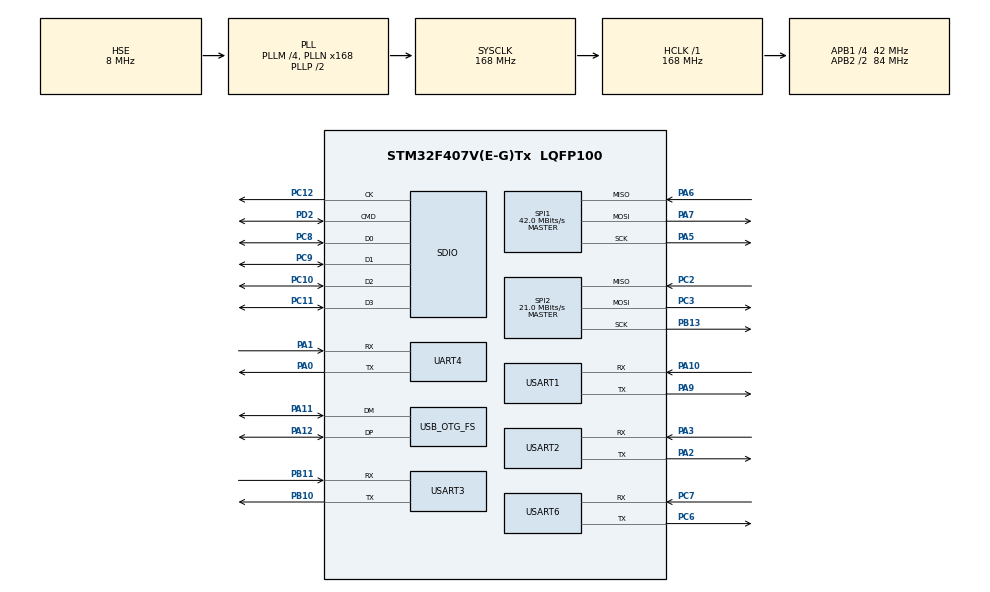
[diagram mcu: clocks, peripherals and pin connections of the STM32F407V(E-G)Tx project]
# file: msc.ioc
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Dma.Request0=SDIO_RX
Dma.Request1=SDIO_TX
Dma.SDIO_RX.0.Direction=DMA_PERIPH_TO_MEMORY
Dma.SDIO_RX.0.FIFOMode=DMA_FIFOMODE_ENABLE
Dma.SDIO_RX.0.FIFOThreshold=DMA_FIFO_THRESHOLD_FULL
Dma.SDIO_RX.0.Instance=DMA2_Stream3
Dma.SDIO_RX.0.MemBurst=DMA_MBURST_INC4
Dma.SDIO_RX.0.MemDataAlignment=DMA_MDATAALIGN_WORD
Dma.SDIO_RX.0.MemInc=DMA_MINC_ENABLE
Dma.SDIO_RX.0.Mode=DMA_PFCTRL
Dma.SDIO_RX.0.PeriphBurst=DMA_PBURST_INC4
Dma.SDIO_RX.0.PeriphDataAlignment=DMA_PDATAALIGN_WORD
Dma.SDIO_RX.0.PeriphInc=DMA_PINC_DISABLE
Dma.SDIO_RX.0.Priority=DMA_PRIORITY_VERY_HIGH
Dma.SDIO_TX.1.Direction=DMA_MEMORY_TO_PERIPH
Dma.SDIO_TX.1.FIFOMode=DMA_FIFOMODE_ENABLE
Dma.SDIO_TX.1.FIFOThreshold=DMA_FIFO_THRESHOLD_FULL
Dma.SDIO_TX.1.Instance=DMA2_Stream6
Dma.SDIO_TX.1.MemBurst=DMA_MBURST_INC4
Dma.SDIO_TX.1.MemDataAlignment=DMA_MDATAALIGN_WORD
Dma.SDIO_TX.1.MemInc=DMA_MINC_ENABLE
Dma.SDIO_TX.1.Mode=DMA_PFCTRL
Dma.SDIO_TX.1.PeriphBurst=DMA_PBURST_INC4
Dma.SDIO_TX.1.PeriphDataAlignment=DMA_PDATAALIGN_WORD
Dma.SDIO_TX.1.PeriphInc=DMA_PINC_DISABLE
Dma.SDIO_TX.1.Priority=DMA_PRIORITY_VERY_HIGH
FATFS.USE_DMA_CODE_SD=1
FATFS._CODE_PAGE=437
FATFS._USE_LFN=1
Mcu.Family=STM32F4
Mcu.Name=STM32F407V(E-G)Tx
Mcu.Package=LQFP100
NVIC.DMA2_Stream3_IRQn=true\:15\:0\:true\:false\:true\:false\:true
NVIC.DMA2_Stream6_IRQn=true\:15\:0\:true\:false\:true\:false\:true
NVIC.HASH_RNG_IRQn=true\:11\:0\:true\:false\:true\:true\:true
NVIC.OTG_FS_IRQn=true\:7\:0\:true\:false\:true\:false\:true
NVIC.PriorityGroup=NVIC_PRIORITYGROUP_4
NVIC.SDIO_IRQn=true\:14\:0\:true\:false\:true\:true\:true
NVIC.SPI1_IRQn=true\:0\:0\:false\:false\:true\:true\:true
NVIC.SPI2_IRQn=true\:0\:0\:false\:false\:true\:true\:true
NVIC.TIM1_CC_IRQn=true\:0\:0\:false\:false\:true\:true\:true
NVIC.UART4_IRQn=true\:0\:0\:false\:false\:true\:true\:true
NVIC.USART1_IRQn=true\:0\:0\:true\:false\:true\:true\:true
NVIC.USART2_IRQn=true\:0\:0\:false\:false\:true\:true\:true
NVIC.USART3_IRQn=true\:0\:0\:false\:false\:true\:true\:true
NVIC.USART6_IRQn=true\:0\:0\:false\:false\:true\:true\:true
PA0-WKUP.Mode=Asynchronous
PA0-WKUP.Signal=UART4_TX
PA1.Mode=Asynchronous
PA1.Signal=UART4_RX
PA10.Mode=Asynchronous
PA10.Signal=USART1_RX
PA11.Mode=Device_Only
PA11.Signal=USB_OTG_FS_DM
PA12.Mode=Device_Only
PA12.Signal=USB_OTG_FS_DP
PA13.Mode=Serial_Wire
PA13.Signal=SYS_JTMS-SWDIO
PA14.Mode=Serial_Wire
PA14.Signal=SYS_JTCK-SWCLK
PA2.Mode=Asynchronous
PA2.Signal=USART2_TX
PA3.Mode=Asynchronous
PA3.Signal=USART2_RX
PA5.Mode=Full_Duplex_Master
PA5.Signal=SPI1_SCK
PA6.Mode=Full_Duplex_Master
PA6.Signal=SPI1_MISO
PA7.Mode=Full_Duplex_Master
PA7.Signal=SPI1_MOSI
PA9.Mode=Asynchronous
PA9.Signal=USART1_TX
PB10.Mode=Asynchronous
PB10.Signal=USART3_TX
PB11.Mode=Asynchronous
PB11.Signal=USART3_RX
PB13.Mode=Full_Duplex_Master
PB13.Signal=SPI2_SCK
PC10.Mode=SD_4_bits_Wide_bus
PC10.Signal=SDIO_D2
PC11.Mode=SD_4_bits_Wide_bus
PC11.Signal=SDIO_D3
PC12.Mode=SD_4_bits_Wide_bus
PC12.Signal=SDIO_CK
PC14-OSC32_IN.Mode=LSE-External-Oscillator
PC14-OSC32_IN.Signal=RCC_OSC32_IN
PC15-OSC32_OUT.Mode=LSE-External-Oscillator
PC15-OSC32_OUT.Signal=RCC_OSC32_OUT
PC2.Mode=Full_Duplex_Master
PC2.Signal=SPI2_MISO
PC3.Mode=Full_Duplex_Master
PC3.Signal=SPI2_MOSI
PC6.Mode=Asynchronous
PC6.Signal=USART6_TX
PC7.Mode=Asynchronous
PC7.Signal=USART6_RX
PC8.Mode=SD_4_bits_Wide_bus
PC8.Signal=SDIO_D0
PC9.Mode=SD_4_bits_Wide_bus
PC9.Signal=SDIO_D1
PD2.Mode=SD_4_bits_Wide_bus
PD2.Signal=SDIO_CMD
PH0-OSC_IN.Mode=HSE-External-Oscillator
PH0-OSC_IN.Signal=RCC_OSC_IN
PH1-OSC_OUT.Mode=HSE-External-Oscillator
PH1-OSC_OUT.Signal=RCC_OSC_OUT
ProjectManager.HeapSize=0x1200
ProjectManager.StackSize=0x800
ProjectManager.TargetToolchain=EWARM V8.32
RCC.48MHZClocksFreq_Value=48000000
RCC.AHBFreq_Value=168000000
RCC.APB1CLKDivider=RCC_HCLK_DIV4
RCC.APB1Freq_Value=42000000
RCC.APB1TimFreq_Value=84000000
RCC.APB2CLKDivider=RCC_HCLK_DIV2
RCC.APB2Freq_Value=84000000
RCC.APB2TimFreq_Value=168000000
RCC.CortexFreq_Value=168000000
RCC.HCLKFreq_Value=168000000
RCC.HSE_VALUE=8000000
RCC.HSI_VALUE=16000000
RCC.PLLM=4
RCC.PLLN=168
RCC.PLLQ=7
RCC.RCC_RTC_Clock_Source=RCC_RTCCLKSOURCE_LSE
RCC.RCC_RTC_Clock_SourceVirtual=RCC_RTCCLKSOURCE_LSE
RCC.SYSCLKFreq_VALUE=168000000
RCC.SYSCLKSource=RCC_SYSCLKSOURCE_PLLCLK
RCC.VCOOutputFreq_Value=336000000
RTC.Alarm=RTC_ALARM_A
SPI1.BaudRatePrescaler=SPI_BAUDRATEPRESCALER_2
SPI1.CalculateBaudRate=42.0 MBits/s
SPI1.Direction=SPI_DIRECTION_2LINES
SPI1.Mode=SPI_MODE_MASTER
SPI1.VirtualType=VM_MASTER
SPI2.CalculateBaudRate=21.0 MBits/s
SPI2.Direction=SPI_DIRECTION_2LINES
SPI2.Mode=SPI_MODE_MASTER
SPI2.VirtualType=VM_MASTER
UART4.VirtualMode=Asynchronous
USART1.VirtualMode=VM_ASYNC
USART2.VirtualMode=VM_ASYNC
USART3.VirtualMode=VM_ASYNC
USART6.VirtualMode=VM_ASYNC
USB_DEVICE.CLASS_NAME_FS=MSC
USB_DEVICE.MSC_MEDIA_PACKET-MSC_FS=4096
USB_DEVICE.VirtualMode-MSC_FS=Msc
USB_DEVICE.VirtualModeFS=Msc_FS
USB_OTG_FS.VirtualMode=Device_Only
VP_FATFS_VS_SDIO.Mode=SDIO
VP_RNG_VS_RNG.Mode=RNG_Activate
VP_RTC_VS_RTC_Activate.Mode=RTC_Enabled
VP_RTC_VS_RTC_Alarm_A_Intern.Mode=Alarm A
VP_RTC_VS_RTC_Calendar.Mode=RTC_Calendar
VP_TIM1_VS_ClockSourceITR.Mode=TriggerSource_ITR0
VP_TIM1_VS_ControllerModeTrigger.Mode=Trigger Mode
VP_USB_DEVICE_VS_USB_DEVICE_MSC_FS.Mode=MSC_FS
board=custom

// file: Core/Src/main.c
/* USER CODE BEGIN Header */
/**
  ******************************************************************************
  * @file           : main.c
  * @brief          : Main program body
  ******************************************************************************
  * @attention
  *
  * <h2><center>&copy; Copyright (c) 2020 STMicroelectronics.
  * All rights reserved.</center></h2>
  *
  * This software component is licensed by ST under Ultimate Liberty license
  * SLA0044, the "License"; You may not use this file except in compliance with
  * the License. You may obtain a copy of the License at:
  *                             www.st.com/SLA0044
  *
  ******************************************************************************
  */
/* USER CODE END Header */
#include "main.h"
#include "dma.h"
#include "fatfs.h"
#include "rng.h"
#include "rtc.h"
#include "sdio.h"
#include "spi.h"
#include "tim.h"
#include "usart.h"
#include "usb_device.h"
#include "gpio.h"

/* USER CODE BEGIN Includes */
#include "fs.h"
/* USER CODE END Includes */

void SystemClock_Config(void);

/* USER CODE BEGIN 0 */
#include "sd_diskio.h"
#include "ff_gen_drv.h"
/* USER CODE END 0 */

int main(void)
{

  /* MCU Configuration--------------------------------------------------------*/

  /* Reset of all peripherals, Initializes the Flash interface and the Systick. */
  HAL_Init();

  /* Configure the system clock */
  SystemClock_Config();

  /* Initialize all configured peripherals */
  MX_GPIO_Init();
  MX_DMA_Init();

  MX_SPI1_Init();
  MX_SDIO_SD_Init();
  MX_UART4_Init();
  MX_USART1_UART_Init();
  MX_USART2_UART_Init();
  MX_USART3_UART_Init();
  MX_USART6_UART_Init();
  MX_RTC_Init();
  MX_SPI2_Init();
  MX_TIM1_Init();
  MX_RNG_Init();
  MX_FATFS_Init();
  MX_USB_DEVICE_Init();

   void W5500_ChipInit(void);
   W5500_ChipInit();
  /* Infinite loop */

  SD_Driver.disk_initialize(0);
  if(SD_Driver.disk_status(0) == 0)
  {

  }
  while (1)
  {
//      file_flush();
        void w5500_test(void);
        w5500_test();
  }
}

void SystemClock_Config(void)
{
  RCC_OscInitTypeDef RCC_OscInitStruct = {0};
  RCC_ClkInitTypeDef RCC_ClkInitStruct = {0};
  RCC_PeriphCLKInitTypeDef PeriphClkInitStruct = {0};

  /** Configure the main internal regulator output voltage
  */
  __HAL_RCC_PWR_CLK_ENABLE();
  __HAL_PWR_VOLTAGESCALING_CONFIG(PWR_REGULATOR_VOLTAGE_SCALE1);
  /** Initializes the RCC Oscillators according to the specified parameters
  * in the RCC_OscInitTypeDef structure.
  */
  RCC_OscInitStruct.OscillatorType = RCC_OSCILLATORTYPE_HSE|RCC_OSCILLATORTYPE_LSE;
  RCC_OscInitStruct.HSEState = RCC_HSE_ON;
  RCC_OscInitStruct.LSEState = RCC_LSE_ON;
  RCC_OscInitStruct.PLL.PLLState = RCC_PLL_ON;
  RCC_OscInitStruct.PLL.PLLSource = RCC_PLLSOURCE_HSE;
  RCC_OscInitStruct.PLL.PLLM = 4;
  RCC_OscInitStruct.PLL.PLLN = 168;
  RCC_OscInitStruct.PLL.PLLP = RCC_PLLP_DIV2;
  RCC_OscInitStruct.PLL.PLLQ = 7;
  if (HAL_RCC_OscConfig(&RCC_OscInitStruct) != HAL_OK)
  {
    Error_Handler();
  }
  /** Initializes the CPU, AHB and APB buses clocks
  */
  RCC_ClkInitStruct.ClockType = RCC_CLOCKTYPE_HCLK|RCC_CLOCKTYPE_SYSCLK
                              |RCC_CLOCKTYPE_PCLK1|RCC_CLOCKTYPE_PCLK2;
  RCC_ClkInitStruct.SYSCLKSource = RCC_SYSCLKSOURCE_PLLCLK;
  RCC_ClkInitStruct.AHBCLKDivider = RCC_SYSCLK_DIV1;
  RCC_ClkInitStruct.APB1CLKDivider = RCC_HCLK_DIV4;
  RCC_ClkInitStruct.APB2CLKDivider = RCC_HCLK_DIV2;

  if (HAL_RCC_ClockConfig(&RCC_ClkInitStruct, FLASH_LATENCY_5) != HAL_OK)
  {
    Error_Handler();
  }
  PeriphClkInitStruct.PeriphClockSelection = RCC_PERIPHCLK_RTC;
  PeriphClkInitStruct.RTCClockSelection = RCC_RTCCLKSOURCE_LSE;
  if (HAL_RCCEx_PeriphCLKConfig(&PeriphClkInitStruct) != HAL_OK)
  {
    Error_Handler();
  }
}

void Error_Handler(void)
{
}

/************************ (C) COPYRIGHT STMicroelectronics *****END OF FILE****/
